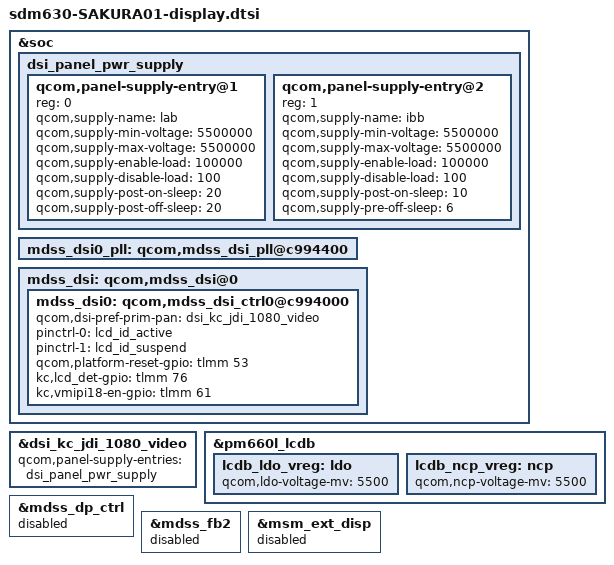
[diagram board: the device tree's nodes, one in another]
/* Copyright (c) 2016-2017, The Linux Foundation. All rights reserved.
 *
 * This program is free software; you can redistribute it and/or modify
 * it under the terms of the GNU General Public License version 2 and
 * only version 2 as published by the Free Software Foundation.
 *
 * This program is distributed in the hope that it will be useful,
 * but WITHOUT ANY WARRANTY; without even the implied warranty of
 * MERCHANTABILITY or FITNESS FOR A PARTICULAR PURPOSE.  See the
 * GNU General Public License for more details.
 */
/*
 * This software is contributed or developed by KYOCERA Corporation.
 * (C) 2018 KYOCERA Corporation
 */

#include "dsi-panel-kc-jdi-1080p-nt35596s-video.dtsi"

&soc {
	dsi_panel_pwr_supply: dsi_panel_pwr_supply {

		/delete-node/ qcom,panel-supply-entry@0;

		qcom,panel-supply-entry@1 {
			reg = <0>;
			qcom,supply-name = "lab";
			qcom,supply-min-voltage = <5500000>;
			qcom,supply-max-voltage = <5500000>;
			qcom,supply-enable-load = <100000>;
			qcom,supply-disable-load = <100>;
			qcom,supply-post-on-sleep = <20>;
			qcom,supply-post-off-sleep = <20>;
		};

		qcom,panel-supply-entry@2 {
			reg = <1>;
			qcom,supply-name = "ibb";
			qcom,supply-min-voltage = <5500000>;
			qcom,supply-max-voltage = <5500000>;
			qcom,supply-enable-load = <100000>;
			qcom,supply-disable-load = <100>;
			qcom,supply-post-on-sleep = <10>;
			qcom,supply-pre-off-sleep = <6>;
		};
	};
	mdss_dsi0_pll: qcom,mdss_dsi_pll@c994400 {
		/delete-property/ qcom,dsi-pll-ssc-en;
		/delete-property/ qcom,dsi-pll-ssc-mode;
	};
	mdss_dsi: qcom,mdss_dsi@0 {
		mdss_dsi0: qcom,mdss_dsi_ctrl0@c994000 {
			/delete-property/ wqhd-vddio-supply;
			/delete-property/ vdda-3p3-supply;
		};
	};
};

&dsi_kc_jdi_1080_video {
	qcom,panel-supply-entries = <&dsi_panel_pwr_supply>;
};

&mdss_dsi0 {
	qcom,dsi-pref-prim-pan = <&dsi_kc_jdi_1080_video>;
	pinctrl-names = "mdss_default", "mdss_sleep";
	pinctrl-0 = <&lcd_id_active>;
	pinctrl-1 = <&lcd_id_suspend>;
	qcom,platform-reset-gpio = <&tlmm 53 0>;
	/delete-property/ qcom,platform-te-gpio;

	kc,lcd_det-gpio = <&tlmm 76 0>;
	kc,vmipi18-en-gpio = <&tlmm 61 0>;
};

/delete-node/ &dsi_nt35695b_truly_fhd_video;
/delete-node/ &dsi_nt35695b_truly_fhd_cmd;
/delete-node/ &dsi_rm67195_amoled_fhd_cmd;

&pm660l_lcdb {
	lcdb_ldo_vreg: ldo {
		qcom,ldo-voltage-mv = <5500>;
	};
	lcdb_ncp_vreg: ncp {
		qcom,ncp-voltage-mv = <5500>;
	};
};

&mdss_dp_ctrl {
	status = "disabled";
};

&mdss_fb2 {
	status = "disabled";
};

&msm_ext_disp {
	status = "disabled";
};
